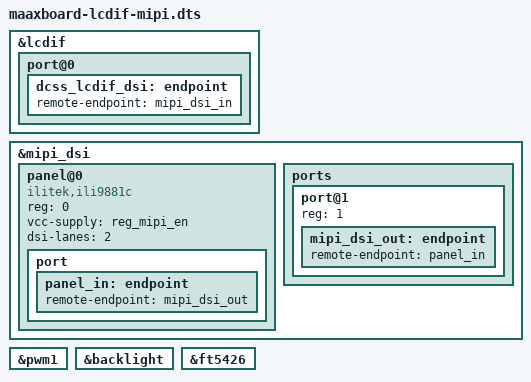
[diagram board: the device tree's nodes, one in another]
/*
 * Copyright 2019 EMBEST
 *
 * This program is free software; you can redistribute it and/or
 * modify it under the terms of the GNU General Public License
 * as published by the Free Software Foundation; either version 2
 * of the License, or (at your option) any later version.
 *
 * This program is distributed in the hope that it will be useful,
 * but WITHOUT ANY WARRANTY; without even the implied warranty of
 * MERCHANTABILITY or FITNESS FOR A PARTICULAR PURPOSE.  See the
 * GNU General Public License for more details.
 */

#include "maaxboard.dtsi"
#include "maaxboard-extended-gpio.dtsi"
#include "maaxboard-dsi-common.dtsi"

&lcdif {
	status = "okay";

	port@0 {
		dcss_lcdif_dsi: endpoint {
			remote-endpoint = <&mipi_dsi_in>;
		};
	};
};

&mipi_dsi {
	status = "okay";

	panel@0 {
		compatible = "ilitek,ili9881c";
		reg = <0>;
		vcc-supply = <&reg_mipi_en>;
		dsi-lanes = <2>;

		port {
			panel_in: endpoint {
				remote-endpoint = <&mipi_dsi_out>;
			};
		};
	};

	ports {
		port@1 {
			reg = <1>;
			mipi_dsi_out: endpoint {
				remote-endpoint = <&panel_in>;
			};
		};
	};
};

&pwm1 {
        status = "okay";
};

&backlight {
	status = "okay";
};

&ft5426 {
	status = "okay";
};
